# rstz_reva register map
Registers are 32-bit, read-write, no defined reset value unless marked. A register's access mark holds for its fields unless they carry their own. Offsets are from the block's base; lines under a group give offsets from that group; [hi:lo] are bit positions; {n}, {i} and the like mark numbered series; 'fields as' and 'values as' point back to an identical list; <NAME> marks a mode.

## Memory map
0x40004800 RSTZ size 0x400 — RSTZ Controller

## RSTZ — RSTZ Controller
Base 0x40004800
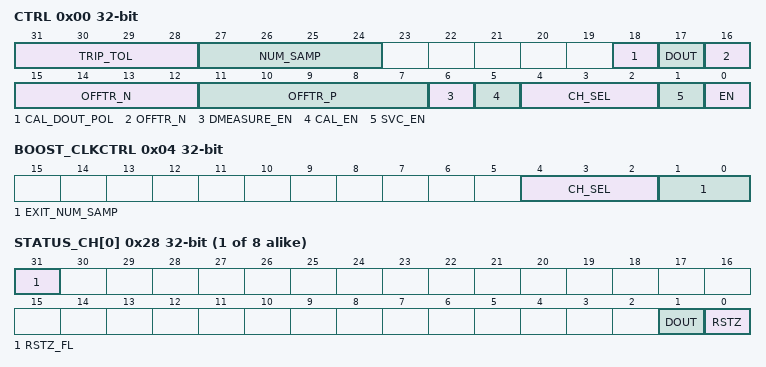
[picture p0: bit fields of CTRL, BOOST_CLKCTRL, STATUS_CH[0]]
0x00 CTRL — RSTZ Control Register.
  [31:28] TRIP_TOL — Number of failed DOUT captures (tolerance) before corresponding RSTZ signal is tripped.
  [27:24] NUM_SAMP — Number of captures per sample.
  [18] CAL_DOUT_POL — Calibration DOUT Polarity.
  [17] DOUT — Comparator Result.
  [16:12] OFFTR_N — Offset Trim for negative comparator.
  [11:7] OFFTR_P — Offset Trim for positive comparator.
  [6] DMEASURE_EN — Direct Measure mode enable.
  [5] CAL_EN — Calibration mode enable.
  [4:2] CH_SEL — Channel Select.
  [1] SVC_EN — Enable the SVC.
  [0] EN — Enable channels.
0x04 BOOST_CLKCTRL size not given — Boost Clock Control Register.
  [4:2] CH_SEL — Select when channel the output of the boost converter is monitored on.
  [1:0] EXIT_NUM_SAMP — Defines how many samples needed of boost output channel to perform when exiting low-power mode before returning to normal active operation.
{0x28+4i} STATUS_CH[{i}] (i=0..7) — Channel X Status Register.
  [31] RSTZ_FL — RSTZ Flag indicates the RSTZ was tripped at some point since the last time being cleared.
  [1] DOUT ro — Store the most recent DOUT capture for a given channel.
  [0] RSTZ ro — Result of most recent sample result.
